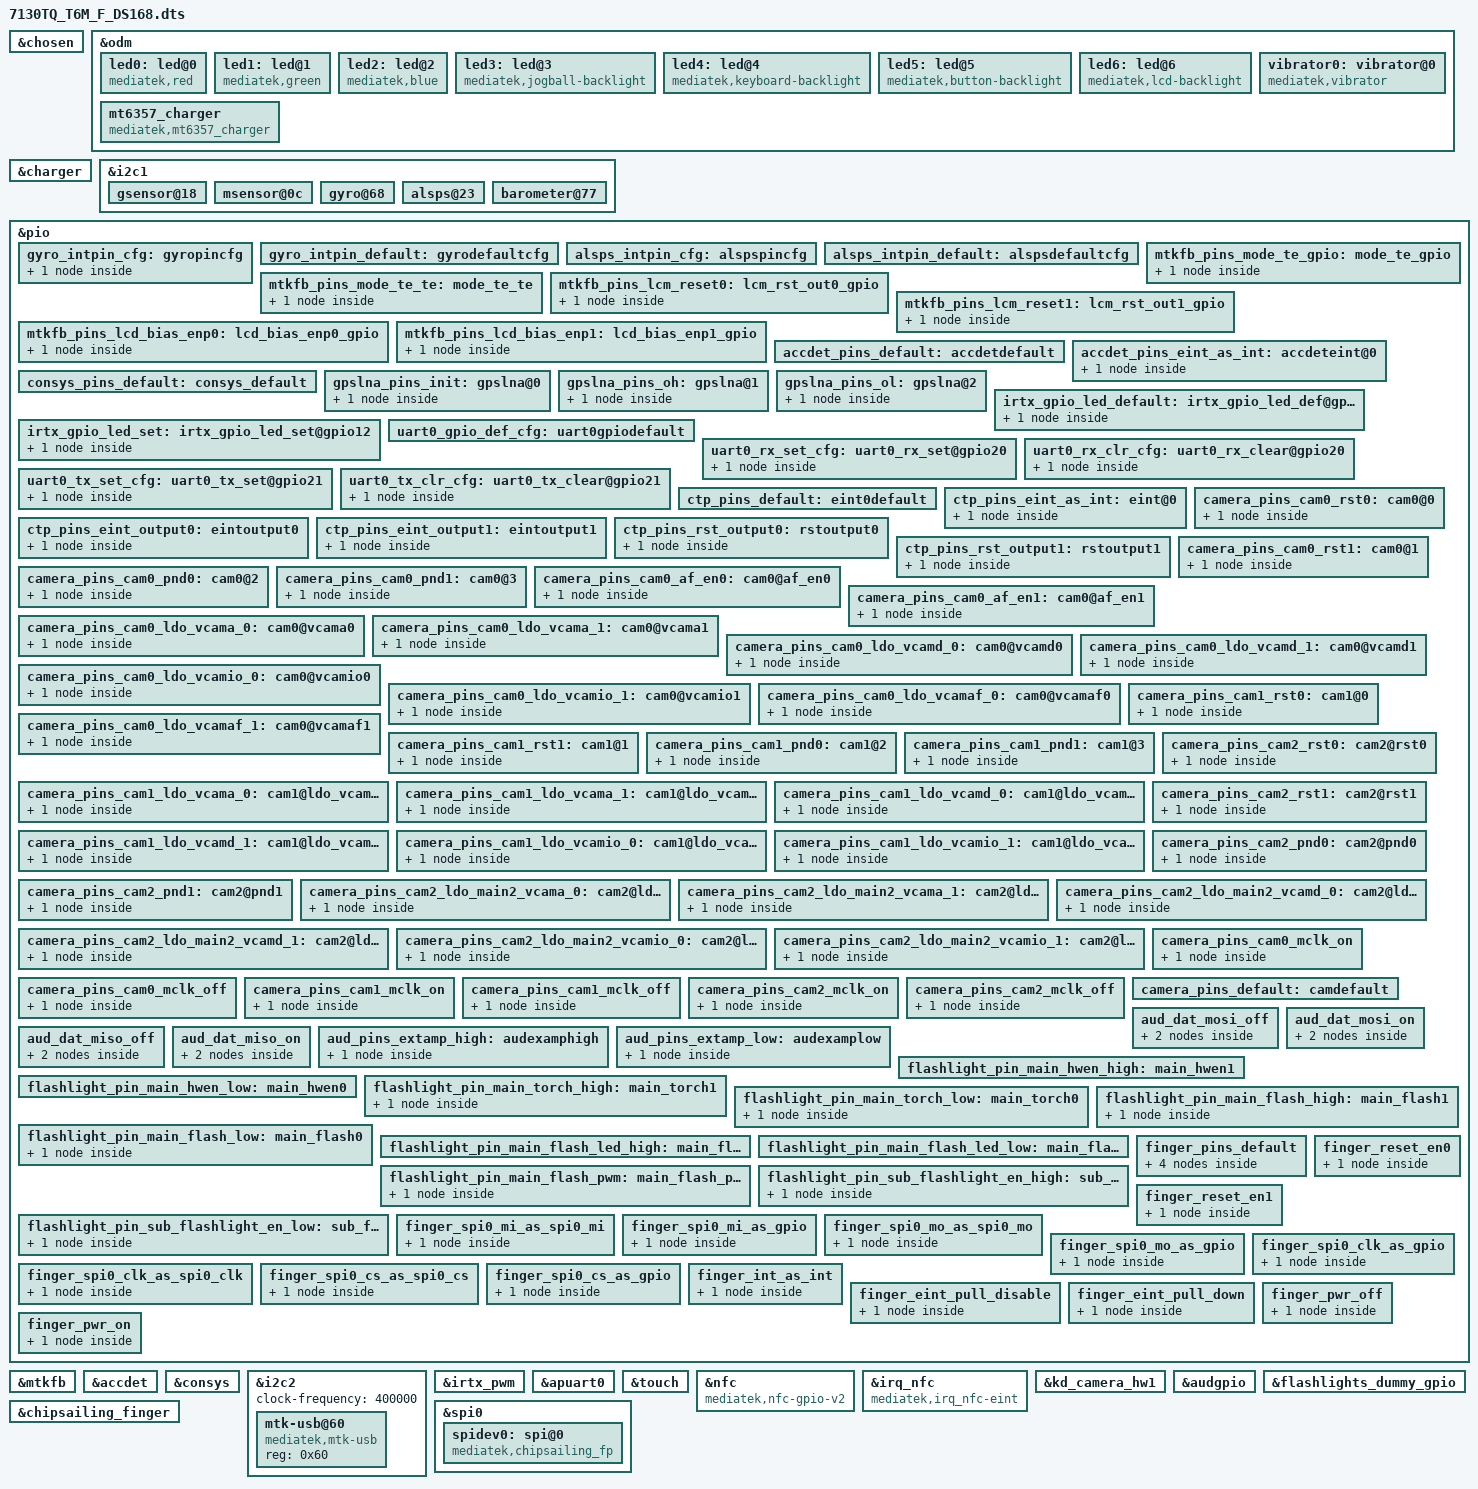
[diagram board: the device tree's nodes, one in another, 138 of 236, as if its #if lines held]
#include <generated/autoconf.h>
/dts-v1/;

#ifdef CONFIG_MTK_DTBO_FEATURE
/plugin/;
#include <dt-bindings/mmc/mt6739-msdc.h>
#include <dt-bindings/pinctrl/mt6739-pinfunc.h>
#else
#include "mt6739.dts"
#endif

/* chosen */
&chosen {
	bootargs = "console=tty0 console=ttyMT0,921600n1 root=/dev/ram initrd=0x44000000,\
0x1000000 loglevel=8 androidboot.selinux=permissive androidboot.hardware=mt6739 initcall_debug=1";
	/* fpga may has no lk, we need to specify display info here */
	/* fb buffer is reserved using this dts by memory node above */

	atag,videolfb-fb_base_l = <0x5e605000>;
	atag,videolfb-fb_base_h = <0>;
	atag,videolfb-islcmfound = <1>;
	atag,videolfb-islcm_inited = <0>;
	atag,videolfb-fps= <6000>;
	atag,videolfb-vramSize= <0x017bb000>;
	atag,videolfb-lcmname= "nt35521_hd_dsi_vdo_truly_nt50358_drv";
};

&odm {
	led0:led@0 {
		compatible = "mediatek,red";
		led_mode = <0>;
		data = <1>;
		pwm_config = <0 0 0 0 0>;
	};
	led1:led@1 {
		compatible = "mediatek,green";
		led_mode = <0>;
		data = <1>;
		pwm_config = <0 0 0 0 0>;
	};
	led2:led@2 {
		compatible = "mediatek,blue";
		led_mode = <0>;
		data = <1>;
		pwm_config = <0 0 0 0 0>;
	};
	led3:led@3 {
		compatible = "mediatek,jogball-backlight";
		led_mode = <0>;
		data = <1>;
		pwm_config = <0 0 0 0 0>;
	};
	led4:led@4 {
		compatible = "mediatek,keyboard-backlight";
		led_mode = <0>;
		data = <1>;
		pwm_config = <0 0 0 0 0>;
	};
	led5:led@5 {
		compatible = "mediatek,button-backlight";
		led_mode = <0>;
		data = <1>;
		pwm_config = <0 0 0 0 0>;
	};
	led6:led@6 {
		compatible = "mediatek,lcd-backlight";
		led_mode = <5>;
		data = <1>;
		pwm_config = <0 2 0 0 0>;
	};
	vibrator0:vibrator@0 {
		compatible = "mediatek,vibrator";
		vib_timer = <25>;
		vib_limit = <9>;
		vib_vol= <9>;
	};

	mt6357_charger {
	  compatible = "mediatek,mt6357_charger";
	  charger_name = "primary_chg";
	  alias_name = "mt6357";
	  ichg = <500000>; /* uA */
	  cv = <4350000>; /* uV */
	  vcdt_hv_thres = <7000000>; /* uV */
	  vbat_ov_thres = <4450000>; /* uV */
	};
};

&charger {
  algorithm_name = "LinearCharging";
  ac_charger_current = <800000>;
  charging_host_charger_current = <800000>;
};


&i2c1 {
/*  start sensor */

	gsensor@18 {
		i2c_num	= <1>;
		i2c_addr = <0x18 0 0 0>;
		direction = <0>;
		power_id = <0xffff>;
		power_vol = <0>;
		firlen = <16>;
		is_batch_supported = <1>;
	};

	msensor@0c {
		i2c_num = <1>;
		i2c_addr = <0x0d 0 0 0>;
		direction = <8>;
		power_id = <0xffff>;
		power_vol = <0>;
		is_batch_supported = <0>;
	};

	gyro@68 {
		pinctrl-names = "pin_default", "pin_cfg";
		pinctrl-0 = <&gyro_intpin_default>;
		pinctrl-1 = <&gyro_intpin_cfg>;
		i2c_num = <1>;
		i2c_addr = <0x68 0 0 0>;
		direction = <5>;
		power_id = <0xffff>;
		power_vol = <0>;
		firlen = <0>;
		is_batch_supported = <0>;
	};

	alsps@23 {
		pinctrl-names = "pin_default", "pin_cfg";
		pinctrl-0 = <&alsps_intpin_default>;
		pinctrl-1 = <&alsps_intpin_cfg>;
		status = "okay";
		/* customization */
		i2c_num = <1>;
		i2c_addr = <0x23 0 0 0>;
		polling_mode_ps = <0>;
		polling_mode_als = <1>;
		power_id = <0xffff>;
		power_vol = <0>;
		als_level = <5   25  50  100  200  400  800  1500 2500 4000  6000  8000  11000 15000 25000>;
		als_value = <40  45  85  100  140  180  240  300  600  1000  2000  3000  4000  8000  10000  10000>;
		ps_threshold_high = <130>;
		ps_threshold_low = <110>;
		is_batch_supported_ps = <0>;
		is_batch_supported_als = <0>;
	};

	barometer@77 {
		i2c_num = <1>;
		i2c_addr = <0x77 0 0 0>;
		direction = <0>;
		power_id = <0xffff>;
		power_vol = <0>;
		firlen = <32>;
		is_batch_supported = <0>;
	};
/* end sensor */
};

/* sensor gpio standization */
&pio {

	gyro_intpin_cfg: gyropincfg {

	    pins_cmd_dat {
			pins = <PINMUX_GPIO5__FUNC_GPIO5>;
			slew-rate = <0>;
			bias-pull-down = <00>;
		};
	};

	gyro_intpin_default: gyrodefaultcfg {

	};
};

&pio {
	alsps_intpin_cfg: alspspincfg {

	};

	alsps_intpin_default: alspsdefaultcfg {

	};
};

/* sensor end */

/* DISPSYS GPIO standardization */
&pio {
	mtkfb_pins_mode_te_gpio: mode_te_gpio {
		pins_cmd_dat {
			pins = <PINMUX_GPIO84__FUNC_DSI_TE>;
		};
	};

	mtkfb_pins_mode_te_te: mode_te_te {
		pins_cmd_dat {
			pins = <PINMUX_GPIO84__FUNC_DSI_TE>;
		};
	};

	mtkfb_pins_lcm_reset0: lcm_rst_out0_gpio {
		pins_cmd_dat {
			pins = <PINMUX_GPIO83__FUNC_LCM_RST>;
			slew-rate = <1>;
			output-low;
		};
	};

	mtkfb_pins_lcm_reset1: lcm_rst_out1_gpio {
		pins_cmd_dat {
			pins = <PINMUX_GPIO83__FUNC_LCM_RST>;
			slew-rate = <1>;
			output-high;
		};
	};

	mtkfb_pins_lcd_bias_enp0: lcd_bias_enp0_gpio {
		pins_cmd_dat {
			pins = <PINMUX_GPIO122__FUNC_GPIO122>;
			slew-rate = <1>;
			output-low;
		};
	};
	mtkfb_pins_lcd_bias_enp1: lcd_bias_enp1_gpio {
		pins_cmd_dat {
			pins = <PINMUX_GPIO122__FUNC_GPIO122>;
			slew-rate = <1>;
			output-high;
		};
	};

};

&mtkfb {
	pinctrl-names = "mode_te_gpio", "mode_te_te", "lcm_rst_out0_gpio",
		"lcm_rst_out1_gpio", "lcd_bias_enp0_gpio", "lcd_bias_enp1_gpio";
	pinctrl-0 = <&mtkfb_pins_mode_te_gpio>;
	pinctrl-1 = <&mtkfb_pins_mode_te_te>;
	pinctrl-2 = <&mtkfb_pins_lcm_reset0>;
	pinctrl-3 = <&mtkfb_pins_lcm_reset1>;
	pinctrl-4 = <&mtkfb_pins_lcd_bias_enp0>;
	pinctrl-5 = <&mtkfb_pins_lcd_bias_enp1>;
	status = "okay";
};
/* DISPSYS GPIO standardization end */


/* accdet start */
&accdet {
	/* accdet micbias voltage: 0x07,2.7v;0x05,2.5v;0x02,1.9v */
	accdet-mic-vol = <6>;
	headset-mode-setting = <0x500 0x500 1 0x1f0 0x800 0x800 0x20 0x44>;
	accdet-plugout-debounce = <1>;
	/*1:ACC mode, 2:low cost without in bias, 6:low cost with in bias*/
	accdet-mic-mode = <1>;/*2*/
	/* eint_level_trigger: 8,LEVEL_LOW(default);4,LEVEL_HIGH;others,LEVEL_LOW */
	headset-eint-level-pol = <8>;
	/*0--MD_MAX--UP_MAX--DW_MAX*/
	headset-three-key-threshold = <0 80 220 400>;
	headset-three-key-threshold-CDD = <0 121 192 600>;
	/*0--MD_MAX--VOICE_MAX--UP_MAX--DW_MAX*/
	headset-four-key-threshold = <0 58 121 192 400>;
	/* ACCDET GPIO standardization ACC mode no use */
	pinctrl-names = "default", "state_eint_as_int";
	pinctrl-0 = <&accdet_pins_default>;
	pinctrl-1 = <&accdet_pins_eint_as_int>;
	status = "okay";
};
&pio {
	accdet_pins_default: accdetdefault {
	};
	accdet_pins_eint_as_int: accdeteint@0 {
		pins_cmd_dat {
			/*pins = <PINMUX_GPIO11__FUNC_GPIO11>;*/
			slew-rate = <0>;
			bias-disable;
		};
	};
};
/* accdet end */
/* CONSYS GPIO standardization */
&pio {
	consys_pins_default: consys_default {
	};
	gpslna_pins_init: gpslna@0 {
		pins_cmd_dat {
			pins = <PINMUX_GPIO118__FUNC_GPIO118>;
			slew-rate = <0>;
			bias-disable;
			output-low;
		};
	};
	gpslna_pins_oh: gpslna@1 {
		pins_cmd_dat {
			pins = <PINMUX_GPIO118__FUNC_GPIO118>;
			slew-rate = <1>;
			output-high;
		};
	};
	gpslna_pins_ol: gpslna@2 {
		pins_cmd_dat {
			pins = <PINMUX_GPIO118__FUNC_GPIO118>;
			slew-rate = <1>;
			output-low;
		};
	};
};
&consys {
	pinctrl-names = "default", "gps_lna_state_init", "gps_lna_state_oh", "gps_lna_state_ol";
	pinctrl-0 = <&consys_pins_default>;
	pinctrl-1 = <&gpslna_pins_init>;
	pinctrl-2 = <&gpslna_pins_oh>;
	pinctrl-3 = <&gpslna_pins_ol>;
	status = "okay";
};
&i2c2 {
	#address-cells = <1>;
	#size-cells = <0>;
	clock-frequency = <400000>;

	mtk-usb@60 {
		compatible = "mediatek,mtk-usb";
		reg = <0x60>;
		status = "okay";
	};
};

/* IRTX GPIO Start */
&irtx_pwm {
	pinctrl-names = "irtx_gpio_led_default", "irtx_gpio_led_set";
	pinctrl-0 = <&irtx_gpio_led_default>;
	pinctrl-1 = <&irtx_gpio_led_set>;
	status = "okay";
};
&pio {
	/* IRTX GPIO Settings -Start */
	/* default: GPIO0, output, high */
	irtx_gpio_led_default:irtx_gpio_led_def@gpio12 {
		pins_cmd_dat {
			pins = <PINMUX_GPIO12__FUNC_GPIO12>;
			slew-rate = <1>;
			bias-disable;
			output-low;
			input-schmitt-enable = <0>;
		};
	};

	irtx_gpio_led_set:irtx_gpio_led_set@gpio12 {
		pins_cmd_dat {
			pins = <PINMUX_GPIO12__FUNC_PWM1>;
			slew-rate = <1>;
			output-high;
		};
	};
}; /* IRTX GPIO Settings -End */

/* UART GPIO */
&apuart0 {
	pinctrl-names = "uart0_gpio_default",
			"uart0_rx_set",
			"uart0_rx_clear",
			"uart0_tx_set",
			"uart0_tx_clear";
	pinctrl-0 = <&uart0_gpio_def_cfg>;
	pinctrl-1 = <&uart0_rx_set_cfg>;
	pinctrl-2 = <&uart0_rx_clr_cfg>;
	pinctrl-3 = <&uart0_tx_set_cfg>;
	pinctrl-4 = <&uart0_tx_clr_cfg>;
	status = "okay";
};

&pio {
	/* UART GPIO Settings - Start */
	/* UART0: rx set, rx clear, tx clear, tx clear*/
	uart0_gpio_def_cfg:uart0gpiodefault {

	};
	uart0_rx_set_cfg:uart0_rx_set@gpio20 {
		pins_cmd_dat {
			pins = <PINMUX_GPIO20__FUNC_UART0RX>;
		};
	};
	uart0_rx_clr_cfg:uart0_rx_clear@gpio20 {
		pins_cmd_dat {
			pins = <PINMUX_GPIO20__FUNC_GPIO20>;
			slew-rate = <1>;
			output-high;
		};
	};
	uart0_tx_set_cfg:uart0_tx_set@gpio21 {
		pins_cmd_dat {
			pins = <PINMUX_GPIO21__FUNC_UART0TX>;
		};
	};
	uart0_tx_clr_cfg:uart0_tx_clear@gpio21 {
		pins_cmd_dat {
			pins = <PINMUX_GPIO21__FUNC_GPIO21>;
			slew-rate = <1>;
			output-high;
		};
	};
};/* UART GPIO end */

/* TOUCH start */
&touch {
	tpd-resolution = <640 1280>;
	use-tpd-button = <1>;
	tpd-key-num = <3>;
	tpd-key-local= <139 172 158 0>;
	tpd-key-dim-local = <120 1350 120 100 360 1350 120 100 600 1350 120 100 0 0 0 0>;
	tpd-max-touch-num = <5>;
	tpd-filter-enable = <0>;
	tpd-filter-pixel-density = <93>;
	tpd-filter-custom-prameters = <0 0 0 0 0 0 0 0 0 0 0 0>;
	tpd-filter-custom-speed = <0 0 0>;
	pinctrl-names = "default", "state_eint_as_int", "state_eint_output0", "state_eint_output1",
		"state_rst_output0", "state_rst_output1";
	pinctrl-0 = <&ctp_pins_default>;
	pinctrl-1 = <&ctp_pins_eint_as_int>;
	pinctrl-2 = <&ctp_pins_eint_output0>;
	pinctrl-3 = <&ctp_pins_eint_output1>;
	pinctrl-4 = <&ctp_pins_rst_output0>;
	pinctrl-5 = <&ctp_pins_rst_output1>;
	status = "okay";
};
&pio {
	ctp_pins_default: eint0default {
	};
	ctp_pins_eint_as_int: eint@0 {
		pins_cmd_dat {
			pins = <PINMUX_GPIO4__FUNC_GPIO4>;
			slew-rate = <0>;
			bias-disable;
		};
	};
	ctp_pins_eint_output0: eintoutput0 {
		pins_cmd_dat {
			pins = <PINMUX_GPIO4__FUNC_GPIO4>;
			slew-rate = <1>;
			output-low;
		};
	};
	ctp_pins_eint_output1: eintoutput1 {
		pins_cmd_dat {
			pins = <PINMUX_GPIO4__FUNC_GPIO4>;
			slew-rate = <1>;
			output-high;
		};
	};
	ctp_pins_rst_output0: rstoutput0 {
		pins_cmd_dat {
			pins = <PINMUX_GPIO26__FUNC_GPIO26>;
			slew-rate = <1>;
			output-low;
		};
	};
	ctp_pins_rst_output1: rstoutput1 {
		pins_cmd_dat {
			pins = <PINMUX_GPIO26__FUNC_GPIO26>;
			slew-rate = <1>;
			output-high;
		};
	};
};
/* TOUCH end */

/* NFC start */
&nfc {
	compatible = "mediatek,nfc-gpio-v2";
	gpio-rst = <7>;
	gpio-rst-std = <&pio 7 0x0>;
	gpio-irq = <14>;
	gpio-irq-std = <&pio 14 0x0>;
};

&irq_nfc {
	compatible = "mediatek,irq_nfc-eint";
};
/* NFC end */

/* CAMERA GPIO standardization */
&pio {
/* Main cam0 */
	camera_pins_cam0_rst0: cam0@0 {
		pins_cmd_dat {
			pins = <PINMUX_GPIO29__FUNC_GPIO29>;
			slew-rate = <1>; /*direction 0:in, 1:out*/
			output-low;/*direction out used only. output_low or high*/
		};
	};
	camera_pins_cam0_rst1: cam0@1 {
		pins_cmd_dat {
			pins = <PINMUX_GPIO29__FUNC_GPIO29>;
			slew-rate = <1>;
			output-high;
		};
	};
	camera_pins_cam0_pnd0: cam0@2 {
		pins_cmd_dat {
			pins = <PINMUX_GPIO30__FUNC_GPIO30>;
			slew-rate = <1>;
			output-low;
		};
	};
	camera_pins_cam0_pnd1: cam0@3 {
		pins_cmd_dat {
			pins = <PINMUX_GPIO30__FUNC_GPIO30>;
			slew-rate = <1>;
			output-high;
		};
	};
	camera_pins_cam0_af_en0: cam0@af_en0 {
		pins_cmd_dat {
			pins = <PINMUX_GPIO112__FUNC_GPIO112>;
			slew-rate = <1>; /*direction 0:in, 1:out*/
			output-low;/*direction out used only. output_low or high*/
		};
	};
	camera_pins_cam0_af_en1: cam0@af_en1 {
		pins_cmd_dat {
			pins = <PINMUX_GPIO112__FUNC_GPIO112>;
			slew-rate = <1>;
			output-high;
		};
	};
	
	camera_pins_cam0_ldo_vcama_0: cam0@vcama0 {
		pins_cmd_dat {
			pins = <PINMUX_GPIO93__FUNC_GPIO93>;
			slew-rate = <1>;
			output-low;
		};
	};
	camera_pins_cam0_ldo_vcama_1: cam0@vcama1 {
		pins_cmd_dat {
			pins = <PINMUX_GPIO93__FUNC_GPIO93>;
			slew-rate = <1>;
			output-high;
		};
	};
	camera_pins_cam0_ldo_vcamd_0: cam0@vcamd0 {
		pins_cmd_dat {
			pins = <PINMUX_GPIO2__FUNC_GPIO2>;
			slew-rate = <1>;
			output-low;
		};
	};
	camera_pins_cam0_ldo_vcamd_1: cam0@vcamd1 {
		pins_cmd_dat {
			pins = <PINMUX_GPIO2__FUNC_GPIO2>;
			slew-rate = <1>;
			output-high;
		};
	};
	camera_pins_cam0_ldo_vcamio_0: cam0@vcamio0 {
		pins_cmd_dat {
			pins = <PINMUX_GPIO2__FUNC_GPIO2>;
			slew-rate = <1>;
			output-low;
		};
	};
	camera_pins_cam0_ldo_vcamio_1: cam0@vcamio1 {
		pins_cmd_dat {
			pins = <PINMUX_GPIO2__FUNC_GPIO2>;
			slew-rate = <1>;
			output-high;
		};
	};
	camera_pins_cam0_ldo_vcamaf_0: cam0@vcamaf0 {
		pins_cmd_dat {
			pins = <PINMUX_GPIO2__FUNC_GPIO2>;
			slew-rate = <1>;
			output-low;
		};
	};
	camera_pins_cam0_ldo_vcamaf_1: cam0@vcamaf1 {
		pins_cmd_dat {
			pins = <PINMUX_GPIO2__FUNC_GPIO2>;
			slew-rate = <1>;
			output-high;
		};
	};

/* Sub cam1 */
	camera_pins_cam1_rst0: cam1@0 {
		pins_cmd_dat {
			pins = <PINMUX_GPIO53__FUNC_GPIO53>;
			slew-rate = <1>; /*direction 0:in, 1:out*/
			output-low;/*direction out used only. output_low or high*/
		};
	};
	camera_pins_cam1_rst1: cam1@1 {
		pins_cmd_dat {
			pins = <PINMUX_GPIO53__FUNC_GPIO53>;
			slew-rate = <1>;
			output-high;
		};
	};
	camera_pins_cam1_pnd0: cam1@2 {
		pins_cmd_dat {
			pins = <PINMUX_GPIO50__FUNC_GPIO50>;
			slew-rate = <1>;
			output-low;
		};
	};
	camera_pins_cam1_pnd1: cam1@3 {
		pins_cmd_dat {
			pins = <PINMUX_GPIO50__FUNC_GPIO50>;
			slew-rate = <1>;
			output-high;
		};
	};
	camera_pins_cam1_ldo_vcama_0: cam1@ldo_vcama_0 {
		pins_cmd_dat {
			pins = <PINMUX_GPIO93__FUNC_GPIO93>;
			slew-rate = <1>;
			output-low;
		};
	};
	camera_pins_cam1_ldo_vcama_1: cam1@ldo_vcama_1 {
		pins_cmd_dat {
			pins = <PINMUX_GPIO93__FUNC_GPIO93>;
			slew-rate = <1>; /*direction 0:in, 1:out*/
			output-high;
		};
	};
	camera_pins_cam1_ldo_vcamd_0: cam1@ldo_vcamd_0 {
		pins_cmd_dat {
			pins = <PINMUX_GPIO2__FUNC_GPIO2>;
			slew-rate = <1>;
			output-low;
		};
	};
	camera_pins_cam1_ldo_vcamd_1: cam1@ldo_vcamd_1 {
		pins_cmd_dat {
			pins = <PINMUX_GPIO2__FUNC_GPIO2>;
			slew-rate = <1>; /*direction 0:in, 1:out*/
			output-high;
		};
	};
	camera_pins_cam1_ldo_vcamio_0: cam1@ldo_vcamio_0 {
		pins_cmd_dat {
			pins = <PINMUX_GPIO2__FUNC_GPIO2>;
			slew-rate = <1>;
			output-low;
		};
	};
	camera_pins_cam1_ldo_vcamio_1: cam1@ldo_vcamio_1 {
		pins_cmd_dat {
			pins = <PINMUX_GPIO2__FUNC_GPIO2>;
			slew-rate = <1>; /*direction 0:in, 1:out*/
			output-high;
		};
	};
	
/* Main2 cam2 */
	camera_pins_cam2_rst0: cam2@rst0 {
		pins_cmd_dat {
			pins = <PINMUX_GPIO92__FUNC_GPIO92>;
			slew-rate = <1>; /*direction 0:in, 1:out*/
			output-low;/*direction out used only. output_low or high*/
		};
	};
	camera_pins_cam2_rst1: cam2@rst1 {
		pins_cmd_dat {
			pins = <PINMUX_GPIO92__FUNC_GPIO92>;
			slew-rate = <1>;
			output-high;
		};
	};
	camera_pins_cam2_pnd0: cam2@pnd0 {
		pins_cmd_dat {
			pins = <PINMUX_GPIO96__FUNC_GPIO96>;
			slew-rate = <1>;
			output-low;
		};
	};
	camera_pins_cam2_pnd1: cam2@pnd1 {
		pins_cmd_dat {
			pins = <PINMUX_GPIO96__FUNC_GPIO96>;
			slew-rate = <1>;
			output-high;
		};
	};

	camera_pins_cam2_ldo_main2_vcama_0: cam2@ldo_main2_vcama_0 {
		pins_cmd_dat {
			pins = <PINMUX_GPIO2__FUNC_GPIO2>;
			slew-rate = <1>;
			output-low;
		};
	};
	camera_pins_cam2_ldo_main2_vcama_1: cam2@ldo_main2_vcama_1 {
		pins_cmd_dat {
			pins = <PINMUX_GPIO2__FUNC_GPIO2>;
			slew-rate = <1>; /*direction 0:in, 1:out*/
			output-high;
		};
	};
	camera_pins_cam2_ldo_main2_vcamd_0: cam2@ldo_main2_vcamd_0 {
		pins_cmd_dat {
			pins = <PINMUX_GPIO2__FUNC_GPIO2>;
			slew-rate = <1>;
			output-low;
		};
	};
	camera_pins_cam2_ldo_main2_vcamd_1: cam2@ldo_main2_vcamd_1 {
		pins_cmd_dat {
			pins = <PINMUX_GPIO2__FUNC_GPIO2>;
			slew-rate = <1>; /*direction 0:in, 1:out*/
			output-high;
		};
	};
	camera_pins_cam2_ldo_main2_vcamio_0: cam2@ldo_main2_vcamio_0 {
		pins_cmd_dat {
			pins = <PINMUX_GPIO2__FUNC_GPIO2>;
			slew-rate = <1>;
			output-low;
		};
	};
	camera_pins_cam2_ldo_main2_vcamio_1: cam2@ldo_main2_vcamio_1 {
		pins_cmd_dat {
			pins = <PINMUX_GPIO2__FUNC_GPIO2>;
			slew-rate = <1>; /*direction 0:in, 1:out*/
			output-high;
		};
	};
	
/* mclk cam0 cam1 cam2 */
	camera_pins_cam0_mclk_on: camera_pins_cam0_mclk_on {
		pins_cmd_dat {
			pins = <PINMUX_GPIO126__FUNC_CMMCLK0>;
		};
	};
	camera_pins_cam0_mclk_off: camera_pins_cam0_mclk_off {
		pins_cmd_dat {
			pins = <PINMUX_GPIO126__FUNC_GPIO126>;
		};
	};
	camera_pins_cam1_mclk_on: camera_pins_cam1_mclk_on {
		pins_cmd_dat {
			pins = <PINMUX_GPIO126__FUNC_CMMCLK0>;
		};
	};
	camera_pins_cam1_mclk_off: camera_pins_cam1_mclk_off {
		pins_cmd_dat {
			pins = <PINMUX_GPIO126__FUNC_GPIO126>;
		};
	};
	camera_pins_cam2_mclk_on: camera_pins_cam2_mclk_on {
		pins_cmd_dat {
			pins = <PINMUX_GPIO126__FUNC_CMMCLK0>;
		};
	};
	camera_pins_cam2_mclk_off: camera_pins_cam2_mclk_off {
		pins_cmd_dat {
			pins = <PINMUX_GPIO126__FUNC_GPIO126>;
		};
	};
	camera_pins_default: camdefault {
	};
};

&kd_camera_hw1 {
	pinctrl-names = "default",
			"cam0_rst0", "cam0_rst1", "cam0_pnd0", "cam0_pnd1",
			"cam0_af_en0", "cam0_af_en1",
			"cam0_ldo_vcama_0", "cam0_ldo_vcama_1",
			"cam0_ldo_vcamd_0", "cam0_ldo_vcamd_1",
			"cam0_ldo_vcamio_0", "cam0_ldo_vcamio_1",
			"cam0_ldo_vcamaf_0", "cam0_ldo_vcamaf_1",
			
			"cam1_rst0", "cam1_rst1", "cam1_pnd0", "cam1_pnd1",
			"cam1_ldo_vcama_0", "cam1_ldo_vcama_1", 
			"cam1_ldo_vcamd_0", "cam1_ldo_vcamd_1", 
			"cam1_ldo_vcamio_0", "cam1_ldo_vcamio_1", 
			
			"cam2_rst0", "cam2_rst1", "cam2_pnd0", "cam2_pnd1", 
			"cam2_ldo_main2_vcama_0", "cam2_ldo_main2_vcama_1", 
			"cam2_ldo_main2_vcamd_0", "cam2_ldo_main2_vcamd_1", 
			"cam2_ldo_main2_vcamio_0", "cam2_ldo_main2_vcamio_1", 
			
			"cam0_mclk_on", "cam0_mclk_off", 
			"cam1_mclk_on", "cam1_mclk_off",
			"cam2_mclk_on", "cam2_mclk_off";
	pinctrl-0 = <&camera_pins_default>;
/* Main cam0 */
	pinctrl-1 = <&camera_pins_cam0_rst0>;
	pinctrl-2 = <&camera_pins_cam0_rst1>;
	pinctrl-3 = <&camera_pins_cam0_pnd0>;
	pinctrl-4 = <&camera_pins_cam0_pnd1>;
	
	pinctrl-5 = <&camera_pins_cam0_af_en0>;
	pinctrl-6 = <&camera_pins_cam0_af_en1>;
	
	pinctrl-7 = <&camera_pins_cam0_ldo_vcama_0>;
	pinctrl-8 = <&camera_pins_cam0_ldo_vcama_1>;
	pinctrl-9 = <&camera_pins_cam0_ldo_vcamd_0>;
	pinctrl-10 = <&camera_pins_cam0_ldo_vcamd_1>;
	pinctrl-11 = <&camera_pins_cam0_ldo_vcamio_0>;
	pinctrl-12 = <&camera_pins_cam0_ldo_vcamio_1>;
	pinctrl-13 = <&camera_pins_cam0_ldo_vcamaf_0>;
	pinctrl-14 = <&camera_pins_cam0_ldo_vcamaf_1>;
	
/* Sub cam1 */
	pinctrl-15 = <&camera_pins_cam1_rst0>;
	pinctrl-16 = <&camera_pins_cam1_rst1>;
	pinctrl-17 = <&camera_pins_cam1_pnd0>;
	pinctrl-18 = <&camera_pins_cam1_pnd1>;
	
	pinctrl-19 = <&camera_pins_cam1_ldo_vcama_0>;
	pinctrl-20 = <&camera_pins_cam1_ldo_vcama_1>;
	pinctrl-21 = <&camera_pins_cam1_ldo_vcamd_0>;
	pinctrl-22 = <&camera_pins_cam1_ldo_vcamd_1>;
	pinctrl-23 = <&camera_pins_cam1_ldo_vcamio_0>;
	pinctrl-24 = <&camera_pins_cam1_ldo_vcamio_1>;
	
/* Main2 cam2 */
	pinctrl-25 = <&camera_pins_cam2_rst0>;
	pinctrl-26 = <&camera_pins_cam2_rst1>;
	pinctrl-27 = <&camera_pins_cam2_pnd0>;
	pinctrl-28 = <&camera_pins_cam2_pnd1>;
	
	pinctrl-29 = <&camera_pins_cam2_ldo_main2_vcama_0>;
	pinctrl-30 = <&camera_pins_cam2_ldo_main2_vcama_1>;
	pinctrl-31 = <&camera_pins_cam2_ldo_main2_vcamd_0>;
	pinctrl-32 = <&camera_pins_cam2_ldo_main2_vcamd_1>;
	pinctrl-33 = <&camera_pins_cam2_ldo_main2_vcamio_0>;
	pinctrl-34 = <&camera_pins_cam2_ldo_main2_vcamio_1>;
	
/* mclk cam0 cam1 cam2 */
	pinctrl-35 = <&camera_pins_cam0_mclk_on>;
	pinctrl-36 = <&camera_pins_cam0_mclk_off>;
	pinctrl-37 = <&camera_pins_cam1_mclk_on>;
	pinctrl-38 = <&camera_pins_cam1_mclk_off>;
	pinctrl-39 = <&camera_pins_cam2_mclk_on>;
	pinctrl-40 = <&camera_pins_cam2_mclk_off>;
	
	status = "okay";
};
/* CAMERA GPIO end */

/* AUDIO GPIO standardization */
&audgpio {
	pinctrl-names = "aud_dat_mosi_off",
			"aud_dat_mosi_on",
			"aud_dat_miso_off",
			"aud_dat_miso_on",
			"extamp-pullhigh",
			"extamp-pulllow";
	pinctrl-0 = <&aud_dat_mosi_off>;
	pinctrl-1 = <&aud_dat_mosi_on>;
	pinctrl-2 = <&aud_dat_miso_off>;
	pinctrl-3 = <&aud_dat_miso_on>;
	pinctrl-4 = <&aud_pins_extamp_high>;
	pinctrl-5 = <&aud_pins_extamp_low>;
	status = "okay";
};

&pio {
	aud_dat_mosi_off: aud_dat_mosi_off {
		pins_cmd1_dat {
			pins = <PINMUX_GPIO63__FUNC_GPIO63>;
			input-enable;
			slew-rate = <0>;
			bias-disable;
		};
		pins_cmd2_dat {
			pins = <PINMUX_GPIO64__FUNC_GPIO64>;
			input-enable;
			slew-rate = <0>;
			bias-disable;
		};
	};

	aud_dat_mosi_on: aud_dat_mosi_on {
		pins_cmd1_dat {
			pins = <PINMUX_GPIO63__FUNC_AUD_DAT_MOSI0>;
		};
		pins_cmd2_dat {
			pins = <PINMUX_GPIO64__FUNC_AUD_DAT_MOSI1>;
		};
	};

	aud_dat_miso_off: aud_dat_miso_off {
		pins_cmd1_dat {
			pins = <PINMUX_GPIO67__FUNC_GPIO67>;
			input-enable;
			slew-rate = <0>;
			bias-disable;
		};
		pins_cmd2_dat {
			pins = <PINMUX_GPIO68__FUNC_GPIO68>;
			input-enable;
			slew-rate = <0>;
			bias-disable;
		};
	};

	aud_dat_miso_on: aud_dat_miso_on {
		pins_cmd1_dat {
			pins = <PINMUX_GPIO67__FUNC_AUD_DAT_MISO0>;
		};
		pins_cmd2_dat {
			pins = <PINMUX_GPIO68__FUNC_AUD_DAT_MISO1>;
		};
	};
	aud_pins_extamp_high: audexamphigh {
		pins_cmd_dat {
			pins = <PINMUX_GPIO119__FUNC_GPIO119>;
			slew-rate = <1>;
			output-high;
		};
	};

	aud_pins_extamp_low: audexamplow {
		pins_cmd_dat {
			pins = <PINMUX_GPIO119__FUNC_GPIO119>;
			slew-rate = <1>;
			output-low;
		};
	};

};
/* AUDIO end */
/*flashlight, begin by maliejun, @2017-11-03 16:06:06*/
&pio {
	flashlight_pin_main_hwen_high: main_hwen1 {
	};
	flashlight_pin_main_hwen_low: main_hwen0 {
	};
	flashlight_pin_main_torch_high: main_torch1 {
		pins_cmd_dat {
			pins = <PINMUX_GPIO54__FUNC_GPIO54>;
			slew-rate = <1>;
			output-high;
		};
	};
	flashlight_pin_main_torch_low: main_torch0 {
		pins_cmd_dat {
			pins = <PINMUX_GPIO54__FUNC_GPIO54>;
			slew-rate = <1>;
			output-low;
		};
	};
	flashlight_pin_main_flash_high: main_flash1 {
		pins_cmd_dat {
			pins = <PINMUX_GPIO12__FUNC_GPIO12>;
			slew-rate = <1>;
			output-high;
		};
	};
	flashlight_pin_main_flash_low: main_flash0 {
		pins_cmd_dat {
			pins = <PINMUX_GPIO12__FUNC_GPIO12>;
			slew-rate = <1>;
			output-low;
		};
	};
	flashlight_pin_main_flash_led_high: main_flash_led1 {
	};
	flashlight_pin_main_flash_led_low: main_flash_led0 {
	};
	flashlight_pin_main_flash_pwm: main_flash_pwm {
		pins_cmd_dat {
			pins = <PINMUX_GPIO54__FUNC_PWM2>;
		};
	};
	flashlight_pin_sub_flashlight_en_high: sub_flashlight_en1 {
		pins_cmd_dat {
			pins = <PINMUX_GPIO90__FUNC_GPIO90>;
			slew-rate = <1>;
			output-high;
		};
	};
	flashlight_pin_sub_flashlight_en_low: sub_flashlight_en0 {
		pins_cmd_dat {
			pins = <PINMUX_GPIO90__FUNC_GPIO90>;
			slew-rate = <1>;
			output-low;
		};
	};
};
&flashlights_dummy_gpio{
	pinctrl-names = "hwen_high", "hwen_low", "torch_high", "torch_low", "flash_high", "flash_low", "flash_led_high", "flash_led_low","flash_pwm","sub_flashlight_en_high","sub_flashlight_en_low";
	pinctrl-0 = <&flashlight_pin_main_hwen_high>;
	pinctrl-1 = <&flashlight_pin_main_hwen_low>;
	pinctrl-2 = <&flashlight_pin_main_torch_high>;
	pinctrl-3 = <&flashlight_pin_main_torch_low>;
	pinctrl-4 = <&flashlight_pin_main_flash_high>;
	pinctrl-5 = <&flashlight_pin_main_flash_low>;
	pinctrl-6 = <&flashlight_pin_main_flash_led_high>;
	pinctrl-7 = <&flashlight_pin_main_flash_led_low>;
	pinctrl-8 = <&flashlight_pin_main_flash_pwm>;
	pinctrl-9 = <&flashlight_pin_sub_flashlight_en_high>;
	pinctrl-10 = <&flashlight_pin_sub_flashlight_en_low>;
	status = "okay";
};
/*flashlight, end by maliejun, @2017-11-03 16:06:10*/


/*** modified by wangdong@szba-mobile.com start FINGERPRINT GPIO standardization ***/
#define __THIS_PIN_IS_UNUSED_GPIO_NUM__                  (2)   //The board does not use this GPIO
#define __THIS_PIN_IS_UNUSED_GPIO__                      PINMUX_GPIO2__FUNC_GPIO2 //The board does not use this GPIO

#define __FINGERPRINT_EINT_PIN_NUM__                     (25) 
#define __FINGERPRINT_EINT_PIN_AS_INT__                  PINMUX_GPIO25__FUNC_GPIO25 
#define __FINGERPRINT_EINT_PIN_AS_GPIO__                 PINMUX_GPIO25__FUNC_GPIO25 
#define __FINGERPRINT_RESET_PIN_NUM__                    (118) 
#define __FINGERPRINT_RESET_PIN_AS_GPIO__                PINMUX_GPIO118__FUNC_GPIO118  
 
#define __FINGERPRINT_MO_PIN_AS_MO__     		 PINMUX_GPIO34__FUNC_SPI0_A_MO  
#define __FINGERPRINT_MO_PIN_AS_GPIO__     		 PINMUX_GPIO34__FUNC_GPIO34 
#define __FINGERPRINT_MI_PIN_AS_MI__      		 PINMUX_GPIO33__FUNC_SPI0_A_MI
#define __FINGERPRINT_MI_PIN_AS_GPIO__      		 PINMUX_GPIO33__FUNC_GPIO33

#define __FINGERPRINT_CLK_PIN_AS_CLK__    		 PINMUX_GPIO32__FUNC_SPI0_A_CLK 
#define __FINGERPRINT_CLK_PIN_AS_GPIO__    		 PINMUX_GPIO32__FUNC_GPIO32 
#define __FINGERPRINT_CS_PIN_AS_CS__    		 PINMUX_GPIO31__FUNC_SPI0_A_CSB  
#define __FINGERPRINT_CS_PIN_AS_GPIO__    		 PINMUX_GPIO31__FUNC_GPIO31 
/*** modified by wangdong@szba-mobile.com end FINGERPRINT GPIO standardization ***/

/* chipsailing_finger ctrl start */

&pio {
	finger_pins_default: finger_pins_default {
			pins_cmd_dat {
	      			pins = <__FINGERPRINT_CS_PIN_AS_CS__>;
			};
			pins_cmd2_dat {
				pins = <__FINGERPRINT_CLK_PIN_AS_CLK__>;
			};
			pins_cmd3_dat {
				pins = <__FINGERPRINT_MI_PIN_AS_MI__>;
			};
			pins_cmd4_dat {
				pins = <__FINGERPRINT_MO_PIN_AS_MO__>;
			};
	};
 
	finger_reset_en0: finger_reset_en0 {
			pins_cmd_dat {
				pins = <__FINGERPRINT_RESET_PIN_AS_GPIO__>;
				slew-rate = <1>;
				output-low; 
			};
	};
	finger_reset_en1: finger_reset_en1 {
			pins_cmd_dat {
				pins = <__FINGERPRINT_RESET_PIN_AS_GPIO__>;
				slew-rate = <1>;
				output-high;
			};
	};
	
	finger_spi0_mi_as_spi0_mi: finger_spi0_mi_as_spi0_mi {
		pins_cmd_dat {
			pins = <__FINGERPRINT_MI_PIN_AS_MI__>;
			slew-rate = <0>;
			bias-disable;
			output-low;
			input-schmit-enable = <0>;
		};
	};
	finger_spi0_mi_as_gpio: finger_spi0_mi_as_gpio {
		pins_cmd_dat {
			pins = <__FINGERPRINT_MI_PIN_AS_GPIO__>;
			slew-rate = <0>;
			output-low;
			input-schmit-enable = <0>;
		};
	};
	finger_spi0_mo_as_spi0_mo: finger_spi0_mo_as_spi0_mo {
		pins_cmd_dat {
			pins = <__FINGERPRINT_MO_PIN_AS_MO__>;
			slew-rate = <1>;
			bias-disable;
			output-low;
			input-schmit-enable = <0>;
		};
	};
	finger_spi0_mo_as_gpio: finger_spi0_mo_as_gpio {
		pins_cmd_dat {
			pins = <__FINGERPRINT_MO_PIN_AS_GPIO__>;
			slew-rate = <1>;
			output-low;
			input-schmit-enable = <0>;
		};
	};
	finger_spi0_clk_as_spi0_clk: finger_spi0_clk_as_spi0_clk {
		pins_cmd_dat {
			pins = <__FINGERPRINT_CLK_PIN_AS_CLK__>;
			slew-rate = <1>;
			bias-disable;
			output-low;
			input-schmit-enable = <0>;
		};
	};
	finger_spi0_clk_as_gpio: finger_spi0_clk_as_gpio {
		pins_cmd_dat {
			pins = <__FINGERPRINT_CLK_PIN_AS_GPIO__>;
			slew-rate = <1>;
			output-low;
			input-schmit-enable = <0>;
		};
	};
	finger_spi0_cs_as_spi0_cs: finger_spi0_cs_as_spi0_cs {
		pins_cmd_dat {
			pins = <__FINGERPRINT_CS_PIN_AS_CS__>;
			slew-rate = <1>;
			bias-disable;
			output-low;
			input-schmit-enable = <0>;
		};
	};
	finger_spi0_cs_as_gpio: finger_spi0_cs_as_gpio {
		pins_cmd_dat {
			pins = <__FINGERPRINT_CS_PIN_AS_GPIO__>;
			slew-rate = <1>;
			output-low;
			input-schmit-enable = <0>;
		};
	};
	finger_int_as_int: finger_int_as_int {
		pins_cmd_dat {
			pins = <__FINGERPRINT_EINT_PIN_AS_INT__>;
			slew-rate = <0>;
			bias-pull-up = <00>;
		};
	};
	
	finger_eint_pull_disable: finger_eint_pull_disable { 
			pins_cmd_dat { 
			        pins = <__FINGERPRINT_EINT_PIN_AS_GPIO__>; 
			        slew-rate = <0>; 
			        bias-disable; 
		        }; 
 	}; 
	finger_eint_pull_down: finger_eint_pull_down { 
    			pins_cmd_dat { 
    				pins = <__FINGERPRINT_EINT_PIN_AS_GPIO__>; 
    				slew-rate = <0>; 
    				bias-pull-down = <00>; 
   		}; 
   	};
	finger_pwr_off: finger_pwr_off {
			pins_cmd_dat {
				pins = <__THIS_PIN_IS_UNUSED_GPIO__>;
				slew-rate = <1>;
				output-low;
			};  
	};
	finger_pwr_on: finger_pwr_on {
			pins_cmd_dat {
				pins = <__THIS_PIN_IS_UNUSED_GPIO__>; 
				slew-rate = <1>;
				output-high;
			};  
	};

};


&chipsailing_finger {
	pinctrl-names = "finger_pins_default", "finger_reset_en0", "finger_reset_en1", 
		"finger_spi0_mi_as_spi0_mi","finger_spi0_mi_as_gpio", 
		"finger_spi0_mo_as_spi0_mo","finger_spi0_mo_as_gpio",
		"finger_spi0_clk_as_spi0_clk", "finger_spi0_clk_as_gpio",
		"finger_spi0_cs_as_spi0_cs","finger_spi0_cs_as_gpio",
		"finger_int_as_int", "finger_eint_pull_down","finger_eint_pull_disable", 
		"finger_pwr_off", "finger_pwr_on"; 
			
	pinctrl-0 = <&finger_pins_default>;
	pinctrl-1 = <&finger_reset_en0>;
	pinctrl-2 = <&finger_reset_en1>;
	
	pinctrl-3 = <&finger_spi0_mi_as_spi0_mi>;
	pinctrl-4 = <&finger_spi0_mi_as_gpio>;
	pinctrl-5 = <&finger_spi0_mo_as_spi0_mo>;
	pinctrl-6 = <&finger_spi0_mo_as_gpio>;
	pinctrl-7 = <&finger_spi0_clk_as_spi0_clk>;
	pinctrl-8 = <&finger_spi0_clk_as_gpio>;
	pinctrl-9 = <&finger_spi0_cs_as_spi0_cs>;
	pinctrl-10= <&finger_spi0_cs_as_gpio>;
	pinctrl-11= <&finger_int_as_int>;
		
	pinctrl-12= <&finger_eint_pull_down>;
	pinctrl-13= <&finger_eint_pull_disable>;
	pinctrl-14= <&finger_pwr_off>;
	pinctrl-15= <&finger_pwr_on>;
		
	interrupt-parent = <&pio>;
	interrupts = <__FINGERPRINT_EINT_PIN_NUM__ 2 __FINGERPRINT_EINT_PIN_NUM__ 0>; //#define IRQ_TYPE_EDGE_FALLING   2
	debounce = <__FINGERPRINT_EINT_PIN_NUM__ 0>; 
		
	chipsailing,gpio_rst = <&pio __FINGERPRINT_RESET_PIN_NUM__ 0>;
	chipsailing,gpio_irq = <&pio __FINGERPRINT_EINT_PIN_NUM__ 0>;
	//finger_int_pin = <&pio __FINGERPRINT_EINT_PIN_NUM__ 0>; 
	status = "okay";
};

/* chipsailing_finger ctrl end */


&spi0{
      status = "okay";
      #address-cells = <1> ;
      #size-cells = <0> ;
      spidev0: spi@0 {
            compatible = "mediatek,chipsailing_fp"; 
            reg = <0>;
            spi-max-frequency = <1000000>;
            status = "okay";
	};
};

#include <bird6739tv1_bsp_1g/cust.dtsi>
/* FINGERPRINT end */

